# nrf9230_engb_secure register map
Vendor: Nordic Semiconductor; Series: nRF92; File version: 1
CPU: CM33 r0p4, little endian, MPU, no FPU, 3 interrupt priority bits, 480 interrupts, 4 SAU regions
Registers are 32-bit, read-write, reset 0x0 unless marked. A register's access mark holds for its fields unless they carry their own. Offsets are from the block's base; [hi:lo] are bit positions; lines under a group give offsets from that group; {n}, {i} and the like mark numbered series; 'fields as' and 'values as' point back to an identical list.

## GLOBAL_CAN120_NS — Controller Area Network 0
Base 0x4F8D8000
Same registers: GLOBAL_CAN121_NS 0x4F8DB000, GLOBAL_CAN120_S 0x5F8D8000, GLOBAL_CAN121_S 0x5F8DB000
0x00 TASKS_START wo — Start the CAN peripheral.
  [0] TASKS_START
    1=Trigger task
0x04 TASKS_STOPREQ wo — Request to stop the CAN peripheral
  [0] TASKS_STOPREQ
    1=Trigger task
0x08 TASKS_STOP wo — Stop the CAN peripheral
  [0] TASKS_STOP
    1=Trigger task
{0x100+4i} EVENTS_CORE[{i}] (i=0..1) — Description collection: Event indicating that interrupt n triggered at CAN core
  [0] EVENTS_CORE — Event indicating that interrupt n triggered at CAN core
    0=NotGenerated (Event not generated); 1=Generated (Event generated)
0x108 EVENTS_DMU — Event indicating that interrupt triggered at CAN DMU
  [0] EVENTS_DMU
    values as EVENTS_CORE[0].EVENTS_CORE
0x10C EVENTS_DMA — Event indicating that interrupt triggered at CAN DMA
  [0] EVENTS_DMA
    values as EVENTS_CORE[0].EVENTS_CORE
0x110 EVENTS_READYFORSTOP — Event indicating that the CAN is ready to be stopped
  [0] EVENTS_READYFORSTOP
    values as EVENTS_CORE[0].EVENTS_CORE
0x200 SHORTS — Shortcuts between local events and tasks
  [0] READYFORSTOP_STOP — Shortcut between event READYFORSTOP and task STOP
    0=Disabled (Disable shortcut); 1=Enabled (Enable shortcut)
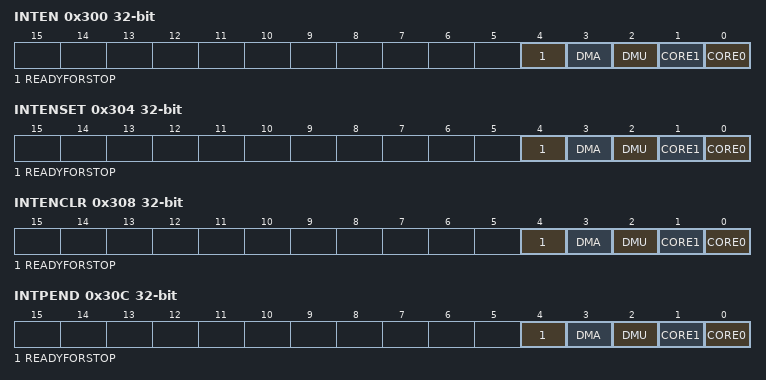
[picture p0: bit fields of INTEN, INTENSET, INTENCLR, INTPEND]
0x300 INTEN — Enable or disable interrupt
  [all] fields
    0=Disabled; 1=Enabled
  [4] READYFORSTOP — Enable or disable interrupt for event READYFORSTOP
  [3] DMA — Enable or disable interrupt for event DMA
  [2] DMU — Enable or disable interrupt for event DMU
  [1] CORE1 — Enable or disable interrupt for event CORE[1]
  [0] CORE0 — Enable or disable interrupt for event CORE[0]
0x304 INTENSET — Enable interrupt
  [all] fields
    on read: 0=Disabled (Read: Disabled); 1=Enabled (Read: Enabled) | on write: 1=Set (Enable)
  [4] READYFORSTOP — Write '1' to enable interrupt for event READYFORSTOP
  [3] DMA — Write '1' to enable interrupt for event DMA
  [2] DMU — Write '1' to enable interrupt for event DMU
  [1] CORE1 — Write '1' to enable interrupt for event CORE[1]
  [0] CORE0 — Write '1' to enable interrupt for event CORE[0]
0x308 INTENCLR — Disable interrupt
  [all] fields
    on read: 0=Disabled (Read: Disabled); 1=Enabled (Read: Enabled) | on write: 1=Clear (Disable)
  [4] READYFORSTOP — Write '1' to disable interrupt for event READYFORSTOP
  [3] DMA — Write '1' to disable interrupt for event DMA
  [2] DMU — Write '1' to disable interrupt for event DMU
  [1] CORE1 — Write '1' to disable interrupt for event CORE[1]
  [0] CORE0 — Write '1' to disable interrupt for event CORE[0]
0x30C INTPEND ro — Pending interrupts
  [all] fields
    on read: 0=NotPending (Read: Not pending); 1=Pending (Read: Pending)
  [4] READYFORSTOP — Read pending status of interrupt for event READYFORSTOP
  [3] DMA — Read pending status of interrupt for event DMA
  [2] DMU — Read pending status of interrupt for event DMU
  [1] CORE1 — Read pending status of interrupt for event CORE[1]
  [0] CORE0 — Read pending status of interrupt for event CORE[0]
0x400 MISC — Register for controlling miscellaneous functions and features of the M_CAN.
  [0] DISMORD — Disable modification on read

## GLOBAL_RAMC122_NS — RAM Controller 0
Base 0x4F8DA000
Same registers: GLOBAL_RAMC123_NS 0x4F8DD000, GLOBAL_RAMC122_S 0x5F8DA000, GLOBAL_RAMC123_S 0x5F8DD000
0x500 WAITSTATES — Waitstates for read operations.
  [0] WAITSTATES — Number of waitstates for a read from the RAM.

## GLOBAL_DPPIC120_NS — Distributed programmable peripheral interconnect controller 0
Base 0x4F8E1000
Same registers: GLOBAL_DPPIC130_NS 0x4F922000, GLOBAL_DPPIC131_NS 0x4F981000, GLOBAL_DPPIC132_NS 0x4F991000, GLOBAL_DPPIC133_NS 0x4F9A1000, GLOBAL_DPPIC134_NS 0x4F9B1000, GLOBAL_DPPIC135_NS 0x4F9C1000, GLOBAL_DPPIC136_NS 0x4F9D1000, GLOBAL_DPPIC120_S 0x5F8E1000, GLOBAL_DPPIC130_S 0x5F922000, GLOBAL_DPPIC131_S 0x5F981000, GLOBAL_DPPIC132_S 0x5F991000, GLOBAL_DPPIC133_S 0x5F9A1000, GLOBAL_DPPIC134_S 0x5F9B1000, GLOBAL_DPPIC135_S 0x5F9C1000, GLOBAL_DPPIC136_S 0x5F9D1000
{0x0+8i} TASKS_CHG[{i}] (i=0..3) group — Channel group tasks
  0x00 EN wo — Description cluster: Enable channel group n
    [0] EN — Enable channel group n
      1=Trigger task
  0x04 DIS wo — Description cluster: Disable channel group n
    [0] DIS — Disable channel group n
      1=Trigger task
{0x80+8i} SUBSCRIBE_CHG[{i}] (i=0..3) group — Subscribe configuration for tasks
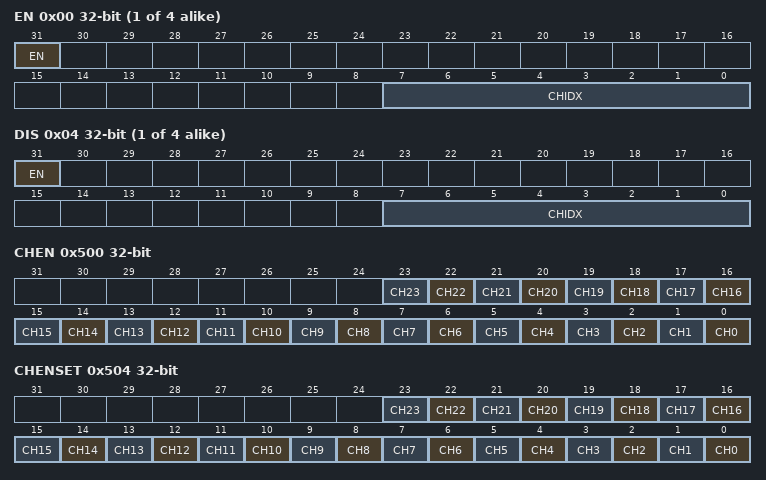
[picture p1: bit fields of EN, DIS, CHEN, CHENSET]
  0x00 EN — Description cluster: Subscribe configuration for task CHG[n].EN
    [31] EN
      0=Disabled (Disable subscription); 1=Enabled (Enable subscription)
    [7:0] CHIDX — DPPI channel that task CHG[n].EN will subscribe to
  0x04 DIS — Description cluster: Subscribe configuration for task CHG[n].DIS
    [31] EN
      values as SUBSCRIBE_CHG[0].EN.EN
    [7:0] CHIDX — DPPI channel that task CHG[n].DIS will subscribe to
0x500 CHEN — Channel enable register
  [all] fields
    0=Disabled (Disable channel); 1=Enabled (Enable channel)
  [n] CH{n} (n=0..23) — Enable or disable channel {n}
0x504 CHENSET write-1-sets — Channel enable set register
  [all] fields
    on read: 0=Disabled (Read: Channel disabled); 1=Enabled (Read: Channel enabled) | on write: 1=Set (Write: Enable channel)
  [n] CH{n} (n=0..23) — Channel {n} enable set register. Writing 0 has no effect.
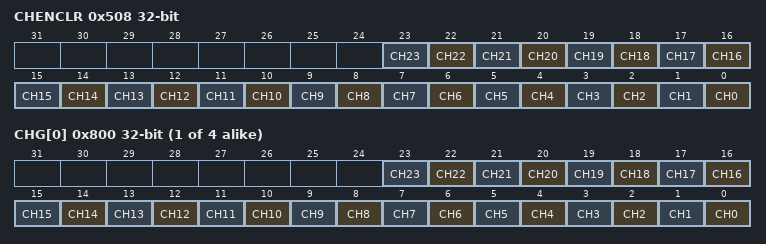
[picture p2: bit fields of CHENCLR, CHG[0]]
0x508 CHENCLR write-1-clears — Channel enable clear register
  [all] fields
    on read: 0=Disabled (Read: Channel disabled); 1=Enabled (Read: Channel enabled) | on write: 1=Clear (Write: Disable channel)
  [n] CH{n} (n=0..23) — Channel {n} enable clear register. Writing 0 has no effect.
{0x800+4i} CHG[{i}] (i=0..3) — Description collection: Channel group n Note: Writes to this register are ignored if either SUBSCRIBE_CHG[n].EN or SUBSCRIBE_CHG[n].DIS is enabled
  [all] fields
    0=Excluded; 1=Included
  [n] CH{n} (n=0..23) — Include or exclude channel {n}
